# pse84_a0 register map
Vendor: Infineon Technologies; Series: PSE84_A0; File version: 1.0
CPU: CM33 r0p1, little endian, MPU, FPU, VTOR, 3 interrupt priority bits
Registers are 32-bit, read-write, reset 0x0 unless marked. A register's access mark holds for its fields unless they carry their own. Offsets are from the block's base; [hi:lo] are bit positions; lines under a group give offsets from that group; {n}, {i} and the like mark numbered series.

## GFXSS (part 3 of 4)
Base 0x44800000
0x2000 GFXSS_MIPIDSI group — MIPI-DSI Host Controller.
  0x00 MXMIPIDSI group — Platform IP standard configuration for MIPI-DSI.
    0x00 CTL — IP control.
      [31] ENABLED — IP enable bit. When disabled (value 0), the functional state of the core is reset. That includes the MMIO map of the core (access results in an AHB error response). Registers of this map are still accesible then.
    0x04 CLK_CTL reset 0x1 — Clock control.
      [0] CLK_CFG — Setup for DPHY configuration clock. Typical value is DIV2. Must only be set to DIV1 if the system clock is not faster than 52 MHz and has a duty cycle of 50 percent. Change only while IP is disabled.
        0=SYS_DIV1 (System clock.); 1=SYS_DIV2 (System clock divided by 2. Enforces correct duty cycle for the configuration clock.)
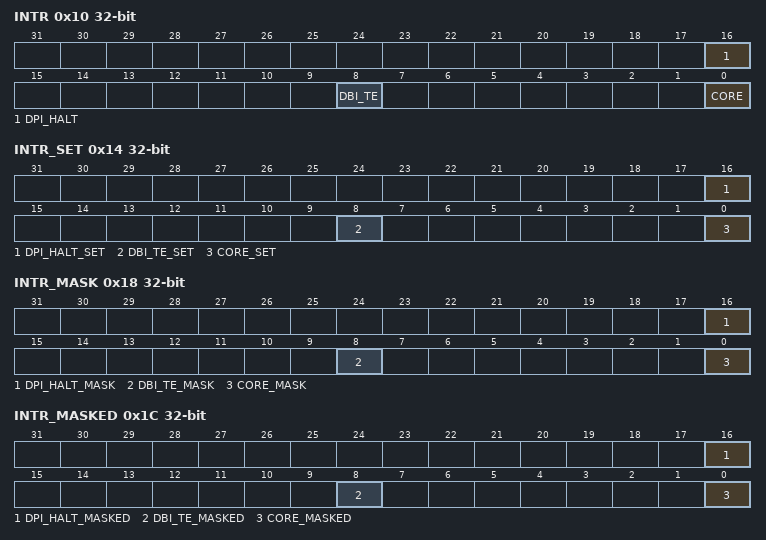
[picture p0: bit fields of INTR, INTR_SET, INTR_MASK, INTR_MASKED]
    0x10 INTR — Interrupt status bits.
      [16] DPI_HALT — Command transmission error occurred in DPI mode. A command initiated by the generic slave interface was too large for transmission during the blanking period of the video timing. Writing a '1' to this field resets the bit.
      [8] DBI_TE — Tearing Effect was signalled by a display in DBI mode. Writing a '1' to this field resets the bit.
      [0] CORE — The DSI Host Controller core has signalled an interrupt. Writing a '1' to this field resets the bit. Interrupt status inside the core is not affected by this.
    0x14 INTR_SET — Interrupt set bits.
      [16] DPI_HALT_SET — Write this field with '1' to set corresponding INTR field (a write of '0' has no effect).
      [8] DBI_TE_SET — Write this field with '1' to set corresponding INTR field (a write of '0' has no effect).
      [0] CORE_SET — Write this field with '1' to set corresponding INTR field (a write of '0' has no effect).
    0x18 INTR_MASK — Interrupt mask bits.
      [16] DPI_HALT_MASK — Mask for corresponding field in INTR register.
      [8] DBI_TE_MASK — Mask for corresponding field in INTR register.
      [0] CORE_MASK — Mask for corresponding field in INTR register.
    0x1C INTR_MASKED ro — Interrupt masked bits.
      [16] DPI_HALT_MASKED — Logical AND of corresponding INTR and INTR_MASK fields.
      [8] DBI_TE_MASKED — Logical AND of corresponding INTR and INTR_MASK fields.
      [0] CORE_MASKED — Logical AND of corresponding INTR and INTR_MASK fields.
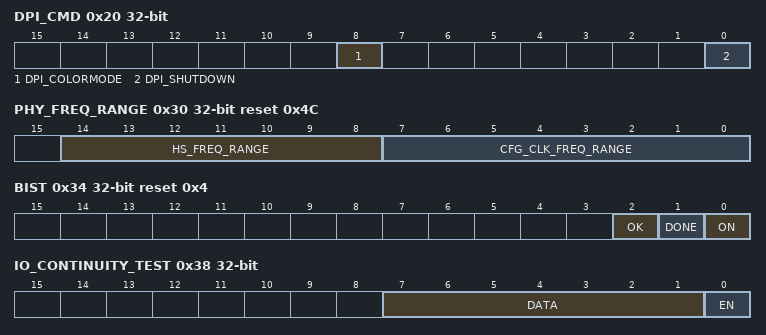
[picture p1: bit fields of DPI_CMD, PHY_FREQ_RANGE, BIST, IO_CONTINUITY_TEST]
    0x20 DPI_CMD — DPI command control.
      [8] DPI_COLORMODE — Turns on/off the color reduction mode of a MIPI-DSI display in DPI mode. The bit is sampled with the next vertical synchronization pulse, so the video timing of the Display Controller must be active for at least one more frame. Polarity depends on the Host Controller configuration.
      [0] DPI_SHUTDOWN — Turns on/off the shutdown mode of a MIPI-DSI display in DPI mode. The bit is sampled with the next vertical synchronization pulse, so the video timing of the Display Controller must be active for at least one more frame. Polarity depends on the Host Controller configuration.
    0x24 DBI_CMD reset 0x1 — DBI command control.
      [0] DBI_RESET — Turns on/off the reset signal for a MIPI-DSI display in DBI mode (low active). The value must only be changed while no DBI command transmission is on-going.
    0x30 PHY_FREQ_RANGE reset 0x4C — PHY frequency range selection.
      [14:8] HS_FREQ_RANGE — High-speed Frequency Range Selection. This signal should be set with the D-PHY in power-down and must not change during operation. This signal can be overridden through D-PHY test control registers.
      [7:0] CFG_CLK_FREQ_RANGE — System clock frequency configuration preset. Should be set according to the following equation: cfgclkfreqrange[7:0] = round[(Fcfg_clk(MHz)-17)*4].
    0x34 BIST reset 0x4 — BIST control.
      [2] OK ro — Indicates the result status. '1' indicates BIST is successful and '0' indicates failure.
      [1] DONE ro — Indicates running status. Value '1' Indicates BIST operation is completed.
      [0] ON — Start/stop for the BIST operation. Assert value '1' to start.
    0x38 IO_CONTINUITY_TEST — IO continuity test control.
      [7:1] DATA ro — Data to observe
      [0] EN — Start/stop for IO continuity test. Assert value '1' to start.
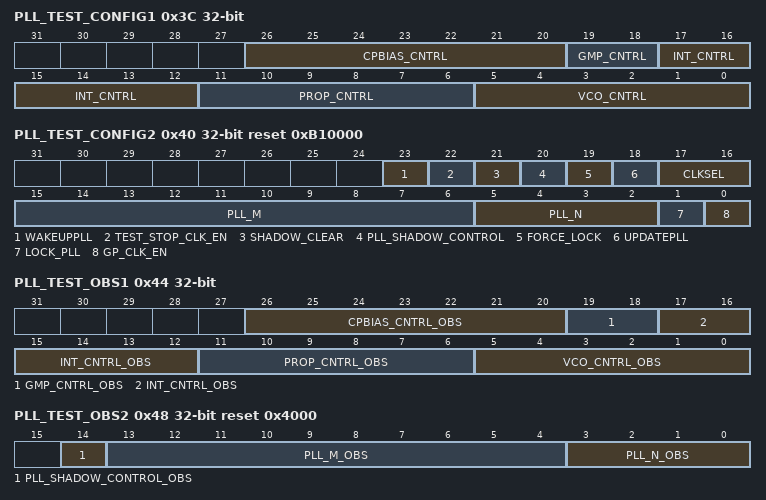
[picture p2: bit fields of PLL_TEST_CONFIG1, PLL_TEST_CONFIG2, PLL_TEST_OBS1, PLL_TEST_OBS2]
    0x3C PLL_TEST_CONFIG1 — PLL-SoC interface configuration for Test.
      [26:20] CPBIAS_CNTRL — Charge pump bias control This signal can be overridden through D-PHY test control registers.
      [19:18] GMP_CNTRL — Control of the effective loop-filter resistance This signal can be overridden through D-PHY test control registers.
      [17:12] INT_CNTRL — Integral charge pump current control This signal can be overridden through D-PHY test control registers.
      [11:6] PROP_CNTRL — Proportional Charge Pump control This signal can be overridden through D-PHY test control registers
      [5:0] VCO_CNTRL — VCO Internal Capacitance Control This signal can be overridden through D-PHY test control registers.
    0x40 PLL_TEST_CONFIG2 reset 0xB10000 — PLL-SoC interface configuration for Test.
      [23] WAKEUPPLL — Wakeuppll signal should be set to 1'b1 during entire operation except when used as part of a relock procedure. This signal has override capability over the PLL boot FSM and allows to trigger a new relock sequence in the system. It is set to 1'b1 during normal operation and pulsed low during at least 1uS during relock sequence (to trigger a new PLL relock).
      [22] TEST_STOP_CLK_EN — Stop clock signal for scan dump support.
      [21] SHADOW_CLEAR — Set to '1' to clear shadow registers.
      [20] PLL_SHADOW_CONTROL — Selection of PLL configuration mechanism. PLL can be configured through D-PHY or through SoC control and shadow control registers: 0: SoC control and shadow registers 1: D-PHY test control register
      [19] FORCE_LOCK — Force lock bit: 0 - according to lock detector-default 1 - lock indication forced
      [18] UPDATEPLL — Control for PLL operation frequency updated. When exercised, PLL SoC control signals are latched to PLL shadow_registers to set PLL operating frequency.
      [17:16] CLKSEL — Control of PLL clock output selection. 00 - Clocks stopped 01 - Clock generation 10 - Buffered clkext 11 - Forbidden
      [15:6] PLL_M — Control of the Feedback Multiplication Ratio M This signal can be overridden through D-PHY test control registers.
      [5:2] PLL_N — Control of the Input Frequency Division Ratio N This signal can be overridden through D-PHY test control registers.
      [1] LOCK_PLL ro — Lock State Signaling. 0: PLL is not locked 1: PLL is locked
      [0] GP_CLK_EN — Enable signal for clkout_gp clock
    0x44 PLL_TEST_OBS1 ro — PLL Test Observation bits.
      [26:20] CPBIAS_CNTRL_OBS — Used for SOC observability of the cpbias_cntrl_obs that is controlling the PLL.
      [19:18] GMP_CNTRL_OBS — Used for SOC observability of the gmp_cntrl_obs that is controlling the PLL.
      [17:12] INT_CNTRL_OBS — Used for SOC observability of the int_cntrl_obs that is controlling the PLL.
      [11:6] PROP_CNTRL_OBS — Used for SOC observability of the prop_cntrl_obs that is controlling the PLL.
      [5:0] VCO_CNTRL_OBS — Output of multiplexer controlled by pll_shadow_control signal. This output signal represents the control signal provided by PHY test control registers or SoC control depending on pll_shadow_control selection. Used for SOC observability of the vco_cntrl_obs that is controlling the PLL
    0x48 PLL_TEST_OBS2 ro reset 0x4000 — PLL Test Observation bits.
      [14] PLL_SHADOW_CONTROL_OBS — Used for SOC observability of the pll_shadow_control_obs that is controlling the PLL
      [13:4] PLL_M_OBS — Used for SOC observability of the m_obs that is controlling the PLL.
      [3:0] PLL_N_OBS — Output of multiplexer controlled by pll_shadow_control signal. This output signal represents the control signal provided by PHY test control registers or SoC control depending on pll_shadow_control selection. Used for SOC observability of the n_obs that is controlling the PLL.
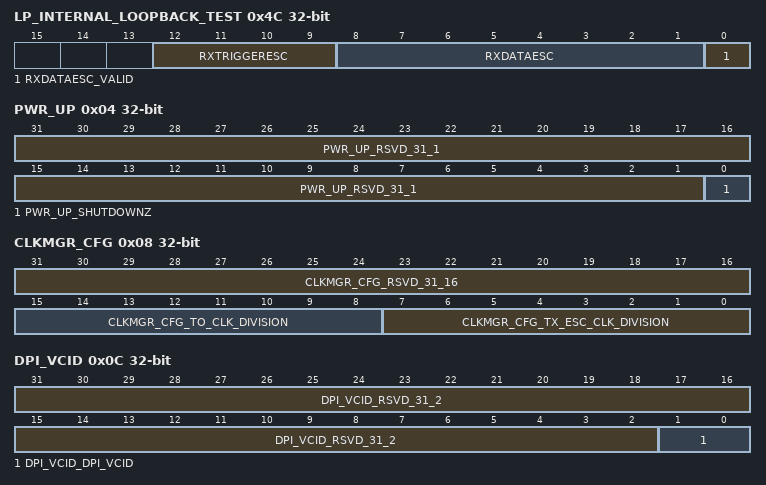
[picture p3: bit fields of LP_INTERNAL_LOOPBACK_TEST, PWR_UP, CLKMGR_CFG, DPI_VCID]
    0x4C LP_INTERNAL_LOOPBACK_TEST ro — Low Power internal Loopback Test
      [12:9] RXTRIGGERESC — Received low power internal loopback data on rxtriggeresc. The TX data can be sent by writing to PHY_TX_TRIGGERS register (one hot encoded)
      [8:1] RXDATAESC — Received low power internal loopback data on rxdataesc. The SW can configure the Generic interface to send short packet with payload size of 2 bytes and the first byte sent would appear on this field, if received successfully.
      [0] RXDATAESC_VALID — Indicate that rxdatasec field is valid. SW can poll this bit before reading the rxdatasec field
  0x1000 DWCMIPIDSI group — DSI Registers
    0x00 VERSION ro reset 0x30313531 — Contains the version of the DSI host controller.
      [31:0] VERSION_VERSION — This field indicates the version of the DWC_mipi_dsi_host.
    0x04 PWR_UP — Controls the power up of the controller.
      [31:1] PWR_UP_RSVD_31_1 ro
      [0] PWR_UP_SHUTDOWNZ — This bit configures the controller either to power up or to reset.
        1=POWERUP ((none)); 0=RESET ((none))
    0x08 CLKMGR_CFG — Configures the factor for internal dividers to divide lanebyteclk for timeout purposes.
      [31:16] CLKMGR_CFG_RSVD_31_16 ro
      [15:8] CLKMGR_CFG_TO_CLK_DIVISION — This field indicates the division factor for the Time Out clock used as the timing unit in the configuration of high-speed to low-power and low-power to high-speed transition error.
      [7:0] CLKMGR_CFG_TX_ESC_CLK_DIVISION — This field indicates the division factor for the TX Escape clock source (lanebyteclk). The values 0 and 1 stop the TX_ESC clock generation.
    0x0C DPI_VCID — Configures the Virtual Channel ID for DPI traffic.
      [31:2] DPI_VCID_RSVD_31_2 ro
      [1:0] DPI_VCID_DPI_VCID — This field configures the DPI virtual channel id that is indexed to the Video mode packets.
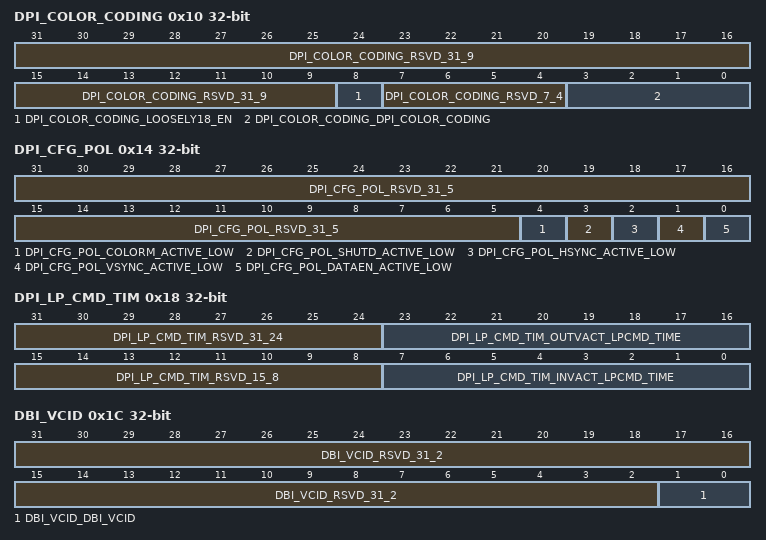
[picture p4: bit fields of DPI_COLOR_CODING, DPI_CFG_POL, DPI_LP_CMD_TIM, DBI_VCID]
    0x10 DPI_COLOR_CODING — Configures DPI color coding.
      [31:9] DPI_COLOR_CODING_RSVD_31_9 ro
      [8] DPI_COLOR_CODING_LOOSELY18_EN — When set to 1, this bit activates loosely packed variant to 18-bit configurations.
      [7:4] DPI_COLOR_CODING_RSVD_7_4 ro
      [3:0] DPI_COLOR_CODING_DPI_COLOR_CODING — This field configures the DPI color for Video Mode/eDPI Command Mode coding as follows:
        {v}=CC{v:02} ((none)) (v=0..15)
    0x14 DPI_CFG_POL — Configures the polarity of DPI signals.
      [31:5] DPI_CFG_POL_RSVD_31_5 ro
      [4] DPI_CFG_POL_COLORM_ACTIVE_LOW — When set to 1, this bit configures the color mode pin (dpicolorm) as active low.
      [3] DPI_CFG_POL_SHUTD_ACTIVE_LOW — When set to 1, this bit configures the shutdown pin (dpishutdn) as active low.
      [2] DPI_CFG_POL_HSYNC_ACTIVE_LOW — When set to 1, this bit configures the horizontal synchronism pin (dpihsync) as active low.
      [1] DPI_CFG_POL_VSYNC_ACTIVE_LOW — When set to 1, this bit configures the vertical synchronism pin (dpivsync) as active low.
      [0] DPI_CFG_POL_DATAEN_ACTIVE_LOW — When set to 1, this bit configures the data enable pin (dpidataen) as active low.
    0x18 DPI_LP_CMD_TIM — Configures the timing for low-power commands sent while in video mode.
      [31:24] DPI_LP_CMD_TIM_RSVD_31_24 ro
      [23:16] DPI_LP_CMD_TIM_OUTVACT_LPCMD_TIME — This field is used for the transmission of commands in low-power mode. It defines the size, in bytes, of the largest packet that can fit in a line during the VSA, VBP, and VFP regions.
      [15:8] DPI_LP_CMD_TIM_RSVD_15_8 ro
      [7:0] DPI_LP_CMD_TIM_INVACT_LPCMD_TIME — This field is used for the transmission of commands in low-power mode. It defines the size, in bytes, of the largest packet that can fit in a line during the VACT region.
    0x1C DBI_VCID — Configures Virtual Channel ID for DBI traffic.
      [31:2] DBI_VCID_RSVD_31_2 ro
      [1:0] DBI_VCID_DBI_VCID — This field configures the virtual channel id that is indexed to the DCS packets from DBI.
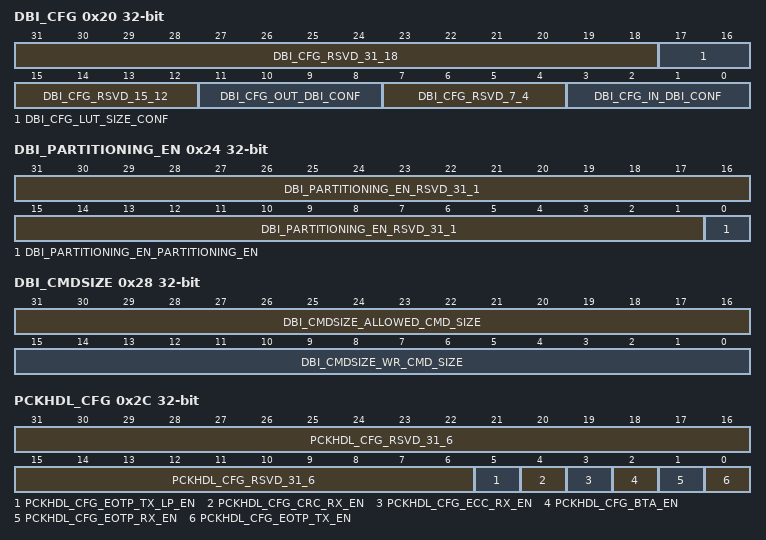
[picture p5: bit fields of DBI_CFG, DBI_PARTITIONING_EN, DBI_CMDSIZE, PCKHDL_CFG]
    0x20 DBI_CFG — Configures the bit width of pixels for DBI.
      [31:18] DBI_CFG_RSVD_31_18 ro
      [17:16] DBI_CFG_LUT_SIZE_CONF — This field configures the size used to transport the Write Lut commands as follows:
        {v}=LUTSIZE{v} ((none)) (v=0..3)
      [15:12] DBI_CFG_RSVD_15_12 ro
      [11:8] DBI_CFG_OUT_DBI_CONF — This field configures the DBI output pixel data as follows:
        {v}=PIXELDATA{v} ((none)) (v=0..12)
      [7:4] DBI_CFG_RSVD_7_4 ro
      [3:0] DBI_CFG_IN_DBI_CONF — This field configures the DBI input pixel data as follows:
        {v}=PIXELDATA{v} ((none)) (v=0..12)
    0x24 DBI_PARTITIONING_EN — Configures whether DWC_mipi_dsi_host is to partition DBI traffic automatically.
      [31:1] DBI_PARTITIONING_EN_RSVD_31_1 ro
      [0] DBI_PARTITIONING_EN_PARTITIONING_EN — When set to 1, this bit enables the use of write_memory_continue input commands (system needs to ensure correct partitioning of Long Write commands). When not set, partitioning is automatically performed in the DWC_mipi_dsi_host.
    0x28 DBI_CMDSIZE — Configures the command size and the size for automatic partitioning of DBI packets.
      [31:16] DBI_CMDSIZE_ALLOWED_CMD_SIZE — This field configures the maximum allowed size for a DCS write memory command. This field is used to partition a write memory command into one write_memory_start and a variable number of write_memory_continue commands. It is only used if the partitioning_en bit of the DBI_CFG register is disabled. The size of the DSI packet payload is the actual payload size minus 1, because the DCS command is in the DSI packet payload.
      [15:0] DBI_CMDSIZE_WR_CMD_SIZE — This field configures the size of the DCS write memory commands. The size of DSI packet payload is the actual payload size minus 1, because the DCS command is in the DSI packet payload.
    0x2C PCKHDL_CFG — Configures how EoTp, BTA, CRC and ECC are to be used, to meet peripherals characteristics
      [31:6] PCKHDL_CFG_RSVD_31_6 ro
      [5] PCKHDL_CFG_EOTP_TX_LP_EN — When set to 1, this bit enables the EoTp transmission in low-power.
      [4] PCKHDL_CFG_CRC_RX_EN — When set to 1, this bit enables the CRC reception and error reporting.
      [3] PCKHDL_CFG_ECC_RX_EN — When set to 1, this bit enables the ECC reception, error correction, and reporting.
      [2] PCKHDL_CFG_BTA_EN — When set to 1, this bit enables the Bus Turn-Around (BTA) request.
      [1] PCKHDL_CFG_EOTP_RX_EN — When set to 1, this bit enables the EoTp reception.
      [0] PCKHDL_CFG_EOTP_TX_EN — When set to 1, this bit enables the EoTp transmission in high-speed.
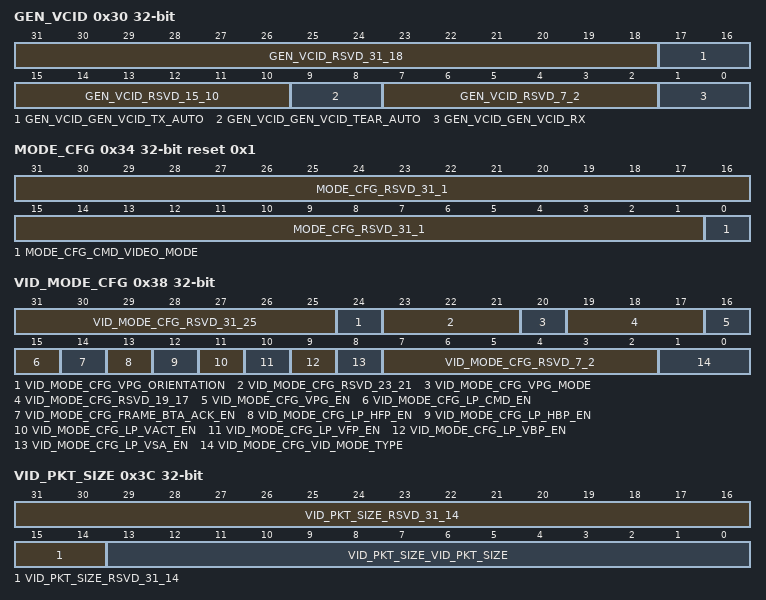
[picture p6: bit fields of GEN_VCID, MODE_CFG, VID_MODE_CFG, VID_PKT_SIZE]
    0x30 GEN_VCID — Configures the Virtual Channel ID of READ responses to store and return to Generic interface.
      [31:18] GEN_VCID_RSVD_31_18 ro
      [17:16] GEN_VCID_GEN_VCID_TX_AUTO — This field indicates the Generic interface virtual channel identification where generic packet is automatically generated & transmitted.
      [15:10] GEN_VCID_RSVD_15_10 ro
      [9:8] GEN_VCID_GEN_VCID_TEAR_AUTO — This field indicates the virtual channel identification for tear effect by hardware
      [7:2] GEN_VCID_RSVD_7_2 ro
      [1:0] GEN_VCID_GEN_VCID_RX — This field indicates the Generic interface read-back virtual channel identification.
    0x34 MODE_CFG reset 0x1 — Configures the mode of operation between Video or Command Mode. (Commands can still be sent while in video mode.)
      [31:1] MODE_CFG_RSVD_31_1 ro
      [0] MODE_CFG_CMD_VIDEO_MODE — This bit configures the operation mode:
        1=CMDMODE ((none)); 0=VIDMODE ((none))
    0x38 VID_MODE_CFG — Configures several aspects of Video mode operation, the transmission mode, switching to low-power in the middle of a frame, enabling acknowledge and whether to send commands in low-power.
      [31:25] VID_MODE_CFG_RSVD_31_25 ro
      [24] VID_MODE_CFG_VPG_ORIENTATION — This field indicates the color bar orientation as follows:
        0=VPGORENT0 ((none)); 1=VPGORENT1 ((none))
      [23:21] VID_MODE_CFG_RSVD_23_21 ro
      [20] VID_MODE_CFG_VPG_MODE — This field is to select the pattern:
        1=BERPATTERN ((none)); 0=COLORBAR ((none))
      [19:17] VID_MODE_CFG_RSVD_19_17 ro
      [16] VID_MODE_CFG_VPG_EN — When set to 1, this bit enables the video mode pattern generator.
      [15] VID_MODE_CFG_LP_CMD_EN — When set to 1, this bit enables the command transmission only in low-power mode.
      [14] VID_MODE_CFG_FRAME_BTA_ACK_EN — When set to 1, this bit enables the request for an acknowledge response at the end of a frame.
      [13] VID_MODE_CFG_LP_HFP_EN — When set to 1, this bit enables the return to low-power inside the HFP period when timing allows.
      [12] VID_MODE_CFG_LP_HBP_EN — When set to 1, this bit enables the return to low-power inside the HBP period when timing allows.
      [11] VID_MODE_CFG_LP_VACT_EN — When set to 1, this bit enables the return to low-power inside the VACT period when timing allows.
      [10] VID_MODE_CFG_LP_VFP_EN — When set to 1, this bit enables the return to low-power inside the VFP period when timing allows.
      [9] VID_MODE_CFG_LP_VBP_EN — When set to 1, this bit enables the return to low-power inside the VBP period when timing allows.
      [8] VID_MODE_CFG_LP_VSA_EN — When set to 1, this bit enables the return to low-power inside the VSA period when timing allows.
      [7:2] VID_MODE_CFG_RSVD_7_2 ro
      [1:0] VID_MODE_CFG_VID_MODE_TYPE — This field indicates the video mode transmission type as follows:
        {v}=VIDMODE{v} ((none)) (v=0..3)
    0x3C VID_PKT_SIZE — Configures the video packet size.
      [31:14] VID_PKT_SIZE_RSVD_31_14 ro
      [13:0] VID_PKT_SIZE_VID_PKT_SIZE — This field configures the number of pixels in a single video packet. - For 18-bit not loosely packed data types, this number must be a multiple of 4. - For YCbCr data types, it must be a multiple of 2, as described in the DSI specification. - For DSC24, this field configures the number of Bytes. Note that when using slices (i.e chunks) the minimum size packet size must be 3.
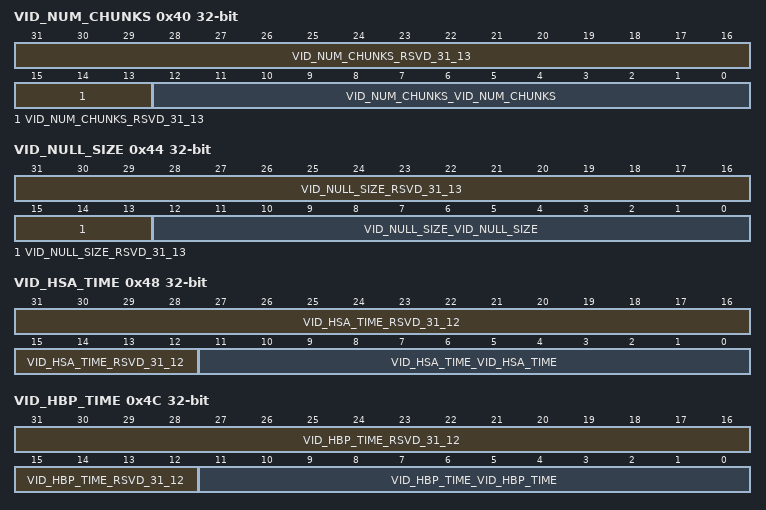
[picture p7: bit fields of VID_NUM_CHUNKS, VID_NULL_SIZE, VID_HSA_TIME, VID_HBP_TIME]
    0x40 VID_NUM_CHUNKS — Configures the number of chunks to use. The data in each chunk has the size provided by VID_PKT_SIZE.
      [31:13] VID_NUM_CHUNKS_RSVD_31_13 ro
      [12:0] VID_NUM_CHUNKS_VID_NUM_CHUNKS — This register configures the number of chunks to be transmitted during a Line period (a chunk is pair made of a video packet and a null packet). If set to 0 or 1, video line is still transmitted in a single packet. If set to 1 that packet is part of a chunk, meaning that a null packet follows it (if vid_null_size>0). Otherwise, multiple chunks are used to transmit each video line.
    0x44 VID_NULL_SIZE — Configures the size of null packets.
      [31:13] VID_NULL_SIZE_RSVD_31_13 ro
      [12:0] VID_NULL_SIZE_VID_NULL_SIZE — This register configures the number of bytes inside a null packet. Setting to 0 disables null packets.
    0x48 VID_HSA_TIME — Configures the video HSA time.
      [31:12] VID_HSA_TIME_RSVD_31_12 ro
      [11:0] VID_HSA_TIME_VID_HSA_TIME — This field configures the Horizontal Synchronism Active period in lane byte clock cycles.
    0x4C VID_HBP_TIME — Configures the video HBP time.
      [31:12] VID_HBP_TIME_RSVD_31_12 ro
      [11:0] VID_HBP_TIME_VID_HBP_TIME — This field configures the Horizontal Back Porch period in lane byte clock cycles.
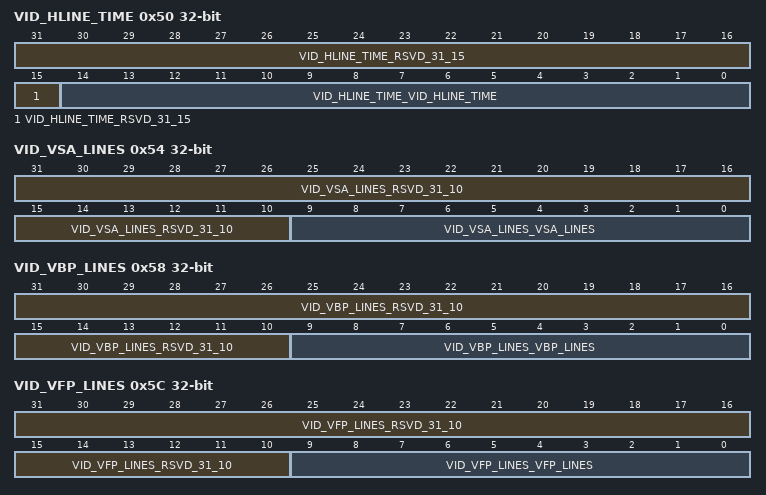
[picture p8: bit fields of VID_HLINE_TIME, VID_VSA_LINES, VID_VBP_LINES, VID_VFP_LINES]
    0x50 VID_HLINE_TIME — Configures the overall time for each video line.
      [31:15] VID_HLINE_TIME_RSVD_31_15 ro
      [14:0] VID_HLINE_TIME_VID_HLINE_TIME — This field configures the size of the total line time (HSA+HBP+HACT+HFP) counted in lane byte clock cycles.
    0x54 VID_VSA_LINES — Configures the VSA period.
      [31:10] VID_VSA_LINES_RSVD_31_10 ro
      [9:0] VID_VSA_LINES_VSA_LINES — This field configures the Vertical Synchronism Active period measured in number of horizontal lines.
    0x58 VID_VBP_LINES — Configures the VBP period.
      [31:10] VID_VBP_LINES_RSVD_31_10 ro
      [9:0] VID_VBP_LINES_VBP_LINES — This field configures the Vertical Back Porch period measured in number of horizontal lines.
    0x5C VID_VFP_LINES — Configures the VFP period.
      [31:10] VID_VFP_LINES_RSVD_31_10 ro
      [9:0] VID_VFP_LINES_VFP_LINES — This field configures the Vertical Front Porch period measured in number of horizontal lines.
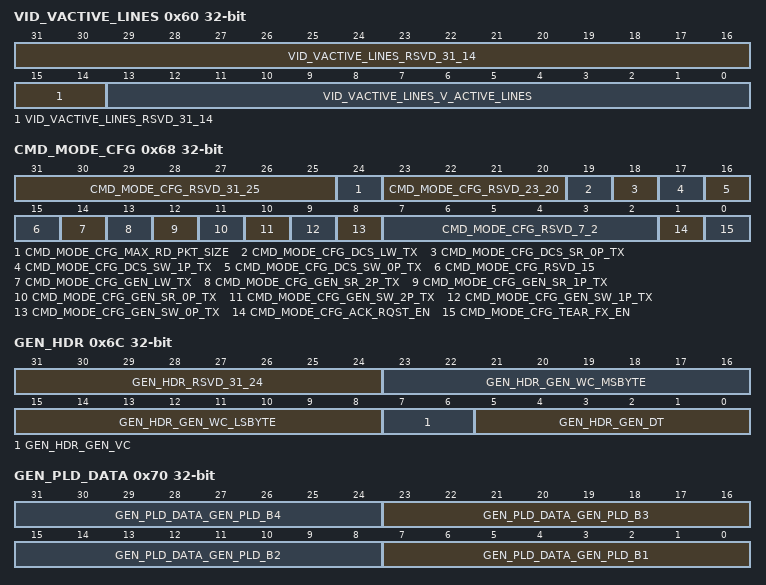
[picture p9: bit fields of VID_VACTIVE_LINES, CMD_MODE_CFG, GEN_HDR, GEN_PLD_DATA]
    0x60 VID_VACTIVE_LINES — Configures the vertical resolution of video.
      [31:14] VID_VACTIVE_LINES_RSVD_31_14 ro
      [13:0] VID_VACTIVE_LINES_V_ACTIVE_LINES — This field configures the Vertical Active period measured in number of horizontal lines.
    0x68 CMD_MODE_CFG — Configures several aspect of command mode operation, tearing effect, acknowledge for each packet and the speed mode to transmit each Data Type related to commands.
      [31:25] CMD_MODE_CFG_RSVD_31_25 ro
      [24] CMD_MODE_CFG_MAX_RD_PKT_SIZE — This bit configures the maximum read packet size command transmission type:
        0=HIGHSPEED ((none)); 1=LOWPOWER ((none))
      [23:20] CMD_MODE_CFG_RSVD_23_20 ro
      [19] CMD_MODE_CFG_DCS_LW_TX — This bit configures the DCS long write packet command transmission type:
        0=HIGHSPEED ((none)); 1=LOWPOWER ((none))
      [18] CMD_MODE_CFG_DCS_SR_0P_TX — This bit configures the DCS short read packet with zero parameter command transmission type:
        0=HIGHSPEED ((none)); 1=LOWPOWER ((none))
      [17] CMD_MODE_CFG_DCS_SW_1P_TX — This bit configures the DCS short write packet with one parameter command transmission type:
        0=HIGHSPEED ((none)); 1=LOWPOWER ((none))
      [16] CMD_MODE_CFG_DCS_SW_0P_TX — This bit configures the DCS short write packet with zero parameter command transmission type:
        0=HIGHSPEED ((none)); 1=LOWPOWER ((none))
      [15] CMD_MODE_CFG_RSVD_15 ro
      [14] CMD_MODE_CFG_GEN_LW_TX — This bit configures the Generic long write packet command transmission type:
        0=HIGHSPEED ((none)); 1=LOWPOWER ((none))
      [13] CMD_MODE_CFG_GEN_SR_2P_TX — This bit configures the Generic short read packet with two parameters command transmission type:
        0=HIGHSPEED ((none)); 1=LOWPOWER ((none))
      [12] CMD_MODE_CFG_GEN_SR_1P_TX — This bit configures the Generic short read packet with one parameter command transmission type:
        0=HIGHSPEED ((none)); 1=LOWPOWER ((none))
      [11] CMD_MODE_CFG_GEN_SR_0P_TX — This bit configures the Generic short read packet with zero parameter command transmission type:
        0=HIGHSPEED ((none)); 1=LOWPOWER ((none))
      [10] CMD_MODE_CFG_GEN_SW_2P_TX — This bit configures the Generic short write packet with two parameters command transmission type:
        0=HIGHSPEED ((none)); 1=LOWPOWER ((none))
      [9] CMD_MODE_CFG_GEN_SW_1P_TX — This bit configures the Generic short write packet with one parameter command transmission type:
        0=HIGHSPEED ((none)); 1=LOWPOWER ((none))
      [8] CMD_MODE_CFG_GEN_SW_0P_TX — This bit configures the Generic short write packet with zero parameter command transmission type:
        0=HIGHSPEED ((none)); 1=LOWPOWER ((none))
      [7:2] CMD_MODE_CFG_RSVD_7_2 ro
      [1] CMD_MODE_CFG_ACK_RQST_EN — When set to 1, this bit enables the acknowledge request after each packet transmission.
      [0] CMD_MODE_CFG_TEAR_FX_EN — When set to 1, this bit enables the tearing effect acknowledge request.
    0x6C GEN_HDR — Sets the header for new packets sent using the Generic interface.
      [31:24] GEN_HDR_RSVD_31_24 ro
      [23:16] GEN_HDR_GEN_WC_MSBYTE — This field configures the most significant byte of the header packet's word count for long packets or data 1 for short packets.
      [15:8] GEN_HDR_GEN_WC_LSBYTE — This field configures the least significant byte of the header packet's Word count for long packets or data 0 for short packets.
      [7:6] GEN_HDR_GEN_VC — This field configures the Virtual Channel ID of the header packet.
      [5:0] GEN_HDR_GEN_DT — This field configures the packet Data Type of the header packet.
    0x70 GEN_PLD_DATA — Sets the payload for packets sent using the Generic interface and, when read returns the contents of READ responses from the peripheral.
      [8n-1:8n-8] GEN_PLD_DATA_GEN_PLD_B{n} (n=1..4) — This field indicates byte {n} of the packet payload.
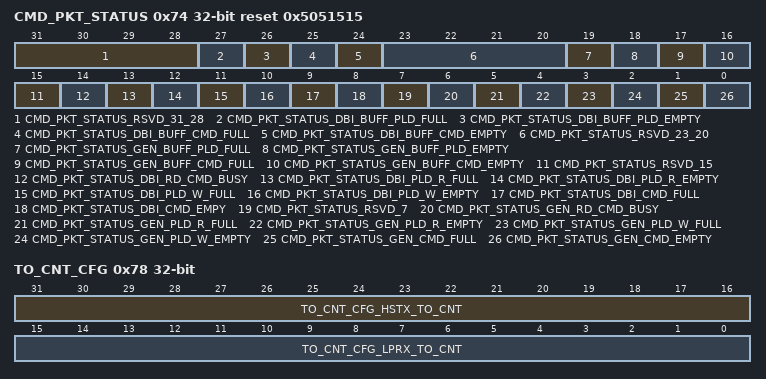
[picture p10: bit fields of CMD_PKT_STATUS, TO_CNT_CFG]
    0x74 CMD_PKT_STATUS ro reset 0x5051515 — Contains information about the status of FIFOs related to DBI and Generic interface.
      [31:28] CMD_PKT_STATUS_RSVD_31_28
      [27] CMD_PKT_STATUS_DBI_BUFF_PLD_FULL — This bit indicates the full status of the DBI payload internal buffer.
      [26] CMD_PKT_STATUS_DBI_BUFF_PLD_EMPTY — This bit indicates the empty status of the DBI payload internal buffer.
      [25] CMD_PKT_STATUS_DBI_BUFF_CMD_FULL — This bit indicates the full status of the DBI command internal buffer.
      [24] CMD_PKT_STATUS_DBI_BUFF_CMD_EMPTY — This bit indicates the empty status of the DBI command internal buffer.
      [23:20] CMD_PKT_STATUS_RSVD_23_20
      [19] CMD_PKT_STATUS_GEN_BUFF_PLD_FULL — This bit indicates the full status of the generic payload internal buffer.
      [18] CMD_PKT_STATUS_GEN_BUFF_PLD_EMPTY — This bit indicates the empty status of the generic payload internal buffer.
      [17] CMD_PKT_STATUS_GEN_BUFF_CMD_FULL — This bit indicates the full status of the generic command internal buffer.
      [16] CMD_PKT_STATUS_GEN_BUFF_CMD_EMPTY — This bit indicates the empty status of the generic command internal buffer.
      [15] CMD_PKT_STATUS_RSVD_15
      [14] CMD_PKT_STATUS_DBI_RD_CMD_BUSY — This bit is set when a read command is issued and cleared when the entire response is stored in the FIFO for DBI interface.
      [13] CMD_PKT_STATUS_DBI_PLD_R_FULL — This bit indicates the full status of the DBI read payload FIFO.
      [12] CMD_PKT_STATUS_DBI_PLD_R_EMPTY — This bit indicates the empty status of the DBI read payload
      [11] CMD_PKT_STATUS_DBI_PLD_W_FULL — This bit indicates the full status of the DBI write payload FIFO.
      [10] CMD_PKT_STATUS_DBI_PLD_W_EMPTY — This bit indicates the empty status of the DBI write payload FIFO.
      [9] CMD_PKT_STATUS_DBI_CMD_FULL — This bit indicates the full status of the DBI command FIFO.
      [8] CMD_PKT_STATUS_DBI_CMD_EMPY — This bit indicates the empty status of the DBI command FIFO.
      [7] CMD_PKT_STATUS_RSVD_7
      [6] CMD_PKT_STATUS_GEN_RD_CMD_BUSY — This bit is set when a read command is issued and cleared when the entire response is stored in the FIFO for GENERIC interface.
      [5] CMD_PKT_STATUS_GEN_PLD_R_FULL — This bit indicates the full status of the generic read payload FIFO.
      [4] CMD_PKT_STATUS_GEN_PLD_R_EMPTY — This bit indicates the empty status of the generic read payload FIFO.
      [3] CMD_PKT_STATUS_GEN_PLD_W_FULL — This bit indicates the full status of the generic write payload FIFO.
      [2] CMD_PKT_STATUS_GEN_PLD_W_EMPTY — This bit indicates the empty status of the generic write payload FIFO.
      [1] CMD_PKT_STATUS_GEN_CMD_FULL — This bit indicates the full status of the generic command FIFO.
      [0] CMD_PKT_STATUS_GEN_CMD_EMPTY — This bit indicates the empty status of the generic command FIFO.
    0x78 TO_CNT_CFG — Configures counters that trigger timeout errors. These are used to warn the system of a failure, through an interrupt, and restart the controller in case of unexpected situations that cause deadlock conditions.
      [31:16] TO_CNT_CFG_HSTX_TO_CNT — This field configures the timeout counter that triggers a high-speed transmission timeout contention detection (measured in TO_CLK_DIVISION cycles). If using non-burst mode and there is not sufficient time to switch from high-speed to low-power and back in the period which is from one line data finishing to the next line sync start, the DSI link returns low-power state once per frame, then you should configure the TO_CLK_DIVISION and hstx_to_cnt to satisfy the following formula: hstx_to_cnt * lanebyteclkperiod * TO_CLK_DIVISION >= the time of one FRAME data transmission * (1 + 10 percent) In burst mode, RGB pixel packets are time-compressed, leaving more time during a scan line. So if in burst mode and there is sufficient time to switch from high-speed to low-power and back in the period of time from one line data finishing to the next line sync start, the DSI link can return low-power mode and back in this time interval to save power. If you choose so, you should configure the TO_CLK_DIVISION and hstx_to_cnt to satisfy the following formula: hstx_to_cnt * lanebyteclkperiod * TO_CLK_DIVISION >= the time of one LINE data transmission * (1 + 10 percent)
      [15:0] TO_CNT_CFG_LPRX_TO_CNT — This field configures the timeout counter that triggers a low-power reception timeout contention detection (measured in TO_CLK_DIVISION cycles).
